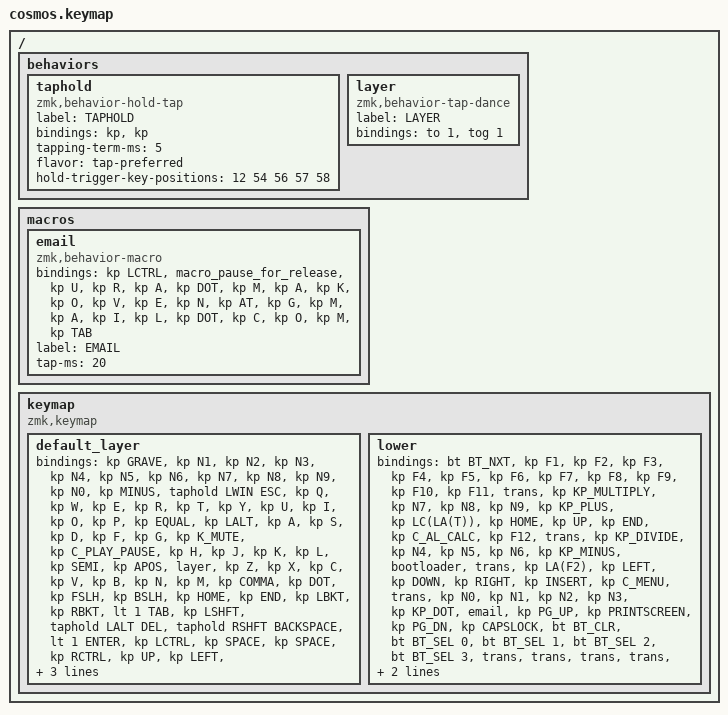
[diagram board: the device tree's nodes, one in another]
/*
 * Copyright (c) 2020 The ZMK Contributors
 *
 * SPDX-License-Identifier: MIT
 */

#include <behaviors.dtsi>
#include <dt-bindings/zmk/bt.h>
#include <dt-bindings/zmk/keys.h>

/ {
    behaviors {
        taphold: taphold {
            compatible = "zmk,behavior-hold-tap";
            label = "TAPHOLD";
            bindings = <&kp>, <&kp>;

            #binding-cells = <2>;
            tapping-term-ms = <5>;
            flavor = "tap-preferred";
            hold-trigger-key-positions = <12 54 56 57 58>;
        };

        layer: layer {
            compatible = "zmk,behavior-tap-dance";
            label = "LAYER";
            #binding-cells = <0>;
            bindings = <&to 1>, <&tog 1>;
        };
    };

    macros {
        email: email {
            compatible = "zmk,behavior-macro";
            #binding-cells = <0>;
            bindings =
                <&kp LCTRL>,
                <&macro_pause_for_release>,
                <&kp U &kp R &kp A &kp DOT &kp M &kp A &kp K &kp O &kp V &kp E &kp N &kp AT &kp G &kp M &kp A &kp I &kp L &kp DOT &kp C &kp O &kp M &kp TAB>;

            label = "EMAIL";
            tap-ms = <20>;
        };
    };

    keymap {
        compatible = "zmk,keymap";

        default_layer {
            bindings = <
&kp GRAVE  &kp N1  &kp N2  &kp N3  &kp N4  &kp N5  &kp N6  &kp N7  &kp N8  &kp N9  &kp N0  &kp MINUS  &taphold LWIN ESC  &kp Q  &kp W  &kp E  &kp R  &kp T  &kp Y  &kp U  &kp I  &kp O  &kp P  &kp EQUAL  &kp LALT  &kp A  &kp S  &kp D  &kp F  &kp G  &kp K_MUTE  &kp C_PLAY_PAUSE  &kp H  &kp J  &kp K  &kp L  &kp SEMI  &kp APOS  &layer  &kp Z  &kp X  &kp C  &kp V  &kp B  &kp N  &kp M  &kp COMMA  &kp DOT  &kp FSLH  &kp BSLH  &kp HOME  &kp END  &kp LBKT  &kp RBKT  &lt 1 TAB  &kp LSHFT  &taphold LALT DEL  &taphold RSHFT BACKSPACE  &lt 1 ENTER  &kp LCTRL  &kp SPACE  &kp SPACE  &kp RCTRL  &kp UP  &kp LEFT  &taphold RALT ENTER  &kp RIGHT  &kp DOWN
            >;

            sensor-bindings =
                <&inc_dec_kp C_VOL_UP C_VOL_DN>,
                <&inc_dec_kp C_PREV C_NEXT>;
        };

        lower {
            bindings = <
&bt BT_NXT  &kp F1  &kp F2  &kp F3  &kp F4  &kp F5  &kp F6  &kp F7  &kp F8  &kp F9  &kp F10  &kp F11  &trans  &kp KP_MULTIPLY  &kp N7  &kp N8  &kp N9  &kp KP_PLUS  &kp LC(LA(T))  &kp HOME  &kp UP  &kp END  &kp C_AL_CALC  &kp F12  &trans  &kp KP_DIVIDE  &kp N4  &kp N5  &kp N6  &kp KP_MINUS  &bootloader  &trans  &kp LA(F2)  &kp LEFT  &kp DOWN  &kp RIGHT  &kp INSERT  &kp C_MENU  &trans  &kp N0  &kp N1  &kp N2  &kp N3  &kp KP_DOT  &email  &kp PG_UP  &kp PRINTSCREEN  &kp PG_DN  &kp CAPSLOCK  &bt BT_CLR  &bt BT_SEL 0  &bt BT_SEL 1  &bt BT_SEL 2  &bt BT_SEL 3  &trans  &trans  &trans  &trans  &trans  &trans  &trans  &trans  &trans  &trans  &trans  &trans  &trans  &trans
            >;
        };
    };
};
